# A31T51x register map
Vendor: ABOV Semiconductor Co., Ltd.; File version: 1.0
CPU: CM0PLUS r0p1, little endian, no MPU, no FPU, VTOR, 2 interrupt priority bits
Registers are 32-bit, read-write, reset 0x0 unless marked. A register's access mark holds for its fields unless they carry their own. Offsets are from the block's base; [hi:lo] are bit positions.

## FRT — Free Run Timer
Base 0x40000600
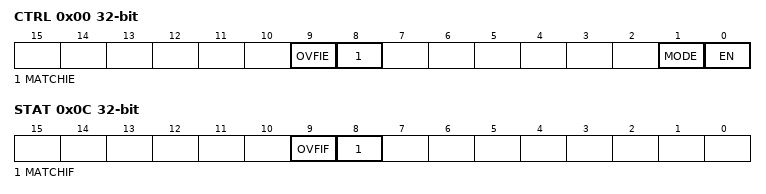
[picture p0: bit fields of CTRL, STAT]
0x00 CTRL — FRT control register
  [9] OVFIE — Whether to enable or disable the FRT counter overflow interrupt in Free-run timer mode (MODE = 0)
    0=Disable (Interrupt Disable); 1=Enable (Interrupt Enable)
  [8] MATCHIE — Whether to enable or disable the FRT counter match interrupt in Periodic timer mode (MODE = 1)
    0=Disable (Interrupt Disable); 1=Enable (Interrupt Enable)
  [1] MODE — FRT mode selection
    0=Free-Run_Timer; 1=Periodic_Timer
  [0] EN — Whether to enable or disable the FRT
    0=Disable (FRT Disable); 1=Enable (FRT Enable)
0x04 MCNT reset 0xFFFFFFFF — FRT match counter register
  [31:0] MCNT — FRTs match counter value
0x08 CNT — FRT counter register
  [31:0] CNT — FRT count data
0x0C STAT — FRT status register
  [9] OVFIF — FRT counter overflow interrupt flag
  [8] MATCHIF — FRT counter match interrupt flag

## SPI — Serial Peripheral Interface Bus
Base 0x40009000
0x00 TDR wo — SPI n Transmit Data Register
  [16:0] TDR — Transmit Data Bit
0x00 RDR ro — SPI n Received Data Register
  [16:0] RDR — Received Data Bit
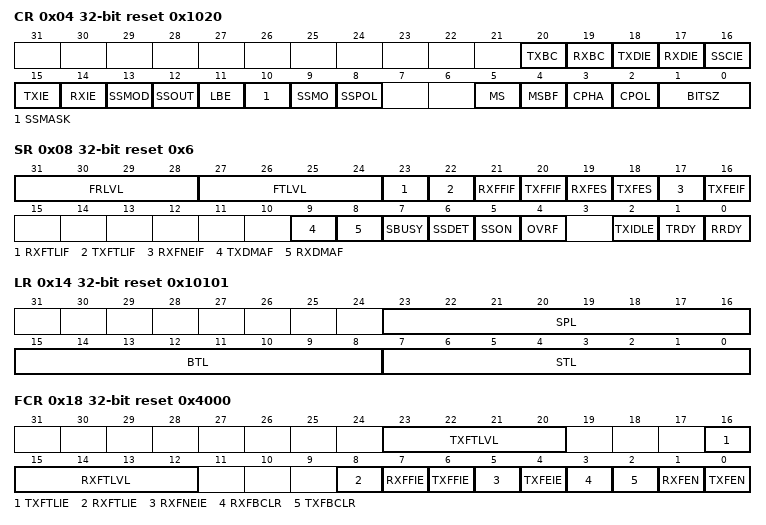
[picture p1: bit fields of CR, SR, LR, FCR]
0x04 CR reset 0x1020 — SPI Control Register
  [20] TXBC wo — Tx Buffer Clear Bit
  [19] RXBC wo — Rx Buffer Clear Bit
  [18] TXDIE — DMA Tx Complete Interrupt Enable Bit
  [17] RXDIE — DMA Rx Complete Interrupt Enable Bit
  [16] SSCIE — SS Edge Changed Interrupt Enable Bit
  [15] TXIE — Transmit Interrupt Enable Bit
  [14] RXIE — Received Interrupt Enable Bit
  [13] SSMOD — SS Auto/Manual Output Selection Bit in Master Mode
  [12] SSOUT — SS Output Signal Control Bit
  [11] LBE — Loop-back Mode Selection Bit in Master Mode
  [10] SSMASK — SS Signal Masking in Slave Mode
  [9] SSMO — SS Output Signal Enable Bit
  [8] SSPOL — SS Signal Polarity Selection Bit
  [5] MS — Master/Slave Selection Bit
  [4] MSBF — MSB/LSB Transmit Advance Selection Bit
  [3] CPHA — SPI Clock Phase Bit
  [2] CPOL — SPI Clock Polarity Bit
  [1:0] BITSZ — Transmit/Receive Bit Size Selection Bit
    0=8_BIT (Size is 8 bit); 1=9_BIT (Size is 9 bit); 2=16_BIT (Size is 16 bit); 3=17_BIT (Size is 17 bit)
0x08 SR reset 0x6 — SPI n Status Register
  [31:28] FRLVL ro — FIFO Reception Level
  [27:24] FTLVL ro — FIFO Transmit Level
  [23] RXFTLIF — Receive FIFO trigger level interrupt flag
  [22] TXFTLIF — Transmit FIFO trigger level interrupt flag
  [21] RXFFIF — Receive FIFO full interrupt flag
  [20] TXFFIF — Transmit FIFO full interrupt flag
  [19] RXFES ro — Receive FIFO empty status
  [18] TXFES ro — Transmit FIFO empty status
  [17] RXFNEIF — Receive FIFO not empty interrupt flag
  [16] TXFEIF — Transmit FIFO empty interrupt flag
  [9] TXDMAF — DMA Transmit Operation Complete Flag
  [8] RXDMAF — DMA Received Operation Complete Flag
  [7] SBUSY ro — Transmit/Received Operating Flag
  [6] SSDET — SS Signal Rising or Falling Edge Detected Flag
  [5] SSON — SS Signal Status Flag
  [4] OVRF — Received Overrun Error Flag
  [2] TXIDLE ro — Transmit Operating Flag
  [1] TRDY ro — Transmit Buffer Empty Flag
  [0] RRDY ro — Received Buffer Empty Flag
0x0C BR reset 0xFFFF — SPI n Baud Rate Register
  [15:0] BR — Baud Rate Setting Bit
0x10 EN — SPI n Enable Register
  [0] ENABLE — SPI Enable Bit
0x14 LR reset 0x10101 — SPI n Delay Length Register
  [23:16] SPL — SPI STOP Length Value Bit
  [15:8] BTL — SPI Burst Length Value Bit
  [7:0] STL — SPI Start Length Value Bit
0x18 FCR reset 0x4000 — SPI n FIFO Control Register
  [23:20] TXFTLVL — Transmit FIFO trigger level select bit.
  [16] TXFTLIE — Transmit FIFO trigger level interrupt enable bit.
  [15:12] RXFTLVL — Receive FIFO trigger level select bit.
  [8] RXFTLIE — Receive FIFO trigger level interrupt enable bit.
  [7] RXFFIE — Receive FIFO full interrupt enable bit.
  [6] TXFFIE — Transmit FIFO full interrupt enable bit.
  [5] RXFNEIE — Receive FIFO not empty interrupt enable bit.
  [4] TXFEIE — Transmit FIFO empty interrupt enable bit.
  [3] RXFBCLR wo — Receive FIFO buffer clear bit. (auto-clear)
  [2] TXFBCLR wo — Transmit FIFO buffer clear bit. (auto-clear)
  [1] RXFEN — Receive FIFO enable bit.
  [0] TXFEN — Transmit FIFO enable bit.
0x1C FTDR — SPI n FIFO Transmit Data Register
  [16:0] FTDR
0x20 FRDR — SPI n FIFO Receive Data Register
  [16:0] FRDR — SPI FIFO Receive Data Register
